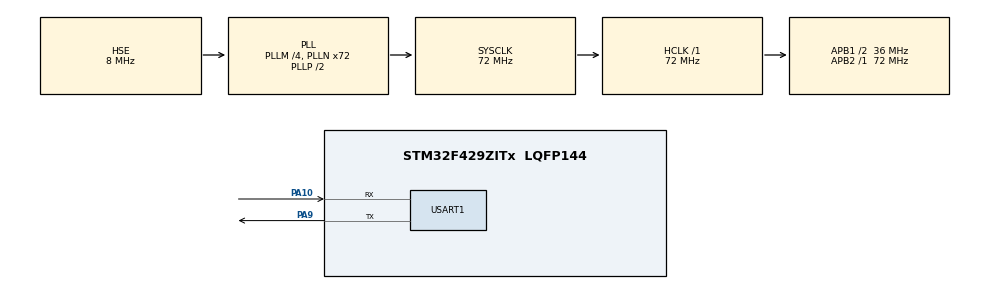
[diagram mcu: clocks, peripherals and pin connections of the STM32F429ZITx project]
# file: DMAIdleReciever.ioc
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Dma.Request0=USART1_RX
Dma.USART1_RX.0.Direction=DMA_PERIPH_TO_MEMORY
Dma.USART1_RX.0.FIFOMode=DMA_FIFOMODE_DISABLE
Dma.USART1_RX.0.Instance=DMA2_Stream2
Dma.USART1_RX.0.MemDataAlignment=DMA_MDATAALIGN_BYTE
Dma.USART1_RX.0.MemInc=DMA_MINC_ENABLE
Dma.USART1_RX.0.Mode=DMA_CIRCULAR
Dma.USART1_RX.0.PeriphDataAlignment=DMA_PDATAALIGN_BYTE
Dma.USART1_RX.0.PeriphInc=DMA_PINC_DISABLE
Dma.USART1_RX.0.Priority=DMA_PRIORITY_LOW
Mcu.Family=STM32F4
Mcu.Name=STM32F429ZITx
Mcu.Package=LQFP144
NVIC.DMA2_Stream2_IRQn=true\:0\:0\:false\:false\:true\:false\:true\:true
NVIC.PriorityGroup=NVIC_PRIORITYGROUP_4
NVIC.USART1_IRQn=true\:0\:0\:false\:false\:true\:true\:true\:true
PA10.Mode=Asynchronous
PA10.Signal=USART1_RX
PA13.Mode=Serial_Wire
PA13.Signal=SYS_JTMS-SWDIO
PA14.Mode=Serial_Wire
PA14.Signal=SYS_JTCK-SWCLK
PA9.Mode=Asynchronous
PA9.Signal=USART1_TX
PH0/OSC_IN.Mode=HSE-External-Oscillator
PH0/OSC_IN.Signal=RCC_OSC_IN
PH1/OSC_OUT.Mode=HSE-External-Oscillator
PH1/OSC_OUT.Signal=RCC_OSC_OUT
ProjectManager.HeapSize=0x200
ProjectManager.StackSize=0x400
ProjectManager.TargetToolchain=STM32CubeIDE
RCC.48MHZClocksFreq_Value=48000000
RCC.AHBFreq_Value=72000000
RCC.APB1CLKDivider=RCC_HCLK_DIV2
RCC.APB1Freq_Value=36000000
RCC.APB1TimFreq_Value=72000000
RCC.APB2Freq_Value=72000000
RCC.APB2TimFreq_Value=72000000
RCC.CortexFreq_Value=72000000
RCC.HCLKFreq_Value=72000000
RCC.HSE_VALUE=8000000
RCC.HSI_VALUE=16000000
RCC.LSE_VALUE=32768
RCC.PLLM=4
RCC.PLLN=72
RCC.PLLQ=3
RCC.PLLSAIN=50
RCC.PLLSourceVirtual=RCC_PLLSOURCE_HSE
RCC.SYSCLKFreq_VALUE=72000000
RCC.SYSCLKSource=RCC_SYSCLKSOURCE_PLLCLK
RCC.VCOOutputFreq_Value=144000000
USART1.VirtualMode=VM_ASYNC
board=STM32F429I-DISC1

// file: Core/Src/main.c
/* USER CODE BEGIN Header */
/**
  ******************************************************************************
  * @file           : main.c
  * @brief          : Main program body
  ******************************************************************************
  * @attention
  *
  * Copyright (c) 2025 STMicroelectronics.
  * All rights reserved.
  *
  * This software is licensed under terms that can be found in the LICENSE file
  * in the root directory of this software component.
  * If no LICENSE file comes with this software, it is provided AS-IS.
  *
  ******************************************************************************
  */
/* USER CODE END Header */
#include "main.h"

/* USER CODE BEGIN Includes */
#include <stdio.h>
#include <string.h>
/* USER CODE END Includes */

DMAIdleReciever_HandleTypeDef hDMAIdleReciever1;
DMA_HandleTypeDef hdma_usart1_rx;

void SystemClock_Config(void);
static void MX_GPIO_Init(void);
static void MX_DMA_Init(void);
static void MX_USART1_DMAIdleReciever_Init(void);

/* USER CODE BEGIN 0 */
#define RXSIZE 256
uint8_t RxData[RXSIZE];
uint8_t FinalBuf[4096];
uint16_t indx1 = 0, indx2=0, rxcplt=0;
int count = 0;
int enable_timer = 0;
uint16_t timer = 0;

void HAL_DMAIdleRecieverEx_RxEventCallback(DMAIdleReciever_HandleTypeDef *hDMAIdleReciever, uint16_t Size)
{
	memcpy (FinalBuf+indx2, RxData+indx1, Size);
	if (Size == RXSIZE)
	{
		rxcplt++;
		indx2 = RXSIZE*rxcplt;
		indx1=0;
	}
	else
	{
		indx2 = indx2 + (Size-indx1);
		indx1 = Size;
	}
	enable_timer = 1;
	timer = 0;

}

/* USER CODE END 0 */

int main(void)
{

  /* MCU Configuration--------------------------------------------------------*/

  /* Reset of all peripherals, Initializes the Flash interface and the Systick. */
  HAL_Init();

  /* Configure the system clock */
  SystemClock_Config();

  /* Initialize all configured peripherals */
  MX_GPIO_Init();
  MX_DMA_Init();
  MX_USART1_DMAIdleReciever_Init();
  /* USER CODE BEGIN 2 */

  HAL_DMAIdleReciever_Transmit(&hDMAIdleReciever1, (uint8_t*)"Hello\r\n", 7, 1000);
  HAL_DMAIdleRecieverEx_ReceiveToIdle_DMA(&hDMAIdleReciever1, RxData, RXSIZE);

  /* USER CODE END 2 */

  /* Infinite loop */
  while (1)
  {

    /* USER CODE BEGIN 3 */
	  if (timer >= 1000){
		  count++;
		  enable_timer = 0;
		  timer=0;
	  }
	/* if (message_ready) {
	  			message_ready = 0;

	  			// Null-terminate for safe string handling
	  			FinalBuf[indx] = '\0';

	  			// Example: Print received GPS/NMEA data back over DMAIdleReciever
	  			char msg[100];
	  			snprintf(msg, sizeof(msg), "Received: %s\r\n", FinalBuf);
	  			HAL_DMAIdleReciever_Transmit(&hDMAIdleReciever1, (uint8_t*) msg, strlen(msg),
	  					HAL_MAX_DELAY);

	  			// Reset buffer
	  			indx = 0;
	  			memset(FinalBuf, 0, sizeof(FinalBuf));
	  		}

	  HAL_Delay(1000);*/

  }
  /* USER CODE END 3 */
}

void SystemClock_Config(void)
{
  RCC_OscInitTypeDef RCC_OscInitStruct = {0};
  RCC_ClkInitTypeDef RCC_ClkInitStruct = {0};

  /** Configure the main internal regulator output voltage
  */
  __HAL_RCC_PWR_CLK_ENABLE();
  __HAL_PWR_VOLTAGESCALING_CONFIG(PWR_REGULATOR_VOLTAGE_SCALE3);

  /** Initializes the RCC Oscillators according to the specified parameters
  * in the RCC_OscInitTypeDef structure.
  */
  RCC_OscInitStruct.OscillatorType = RCC_OSCILLATORTYPE_HSE;
  RCC_OscInitStruct.HSEState = RCC_HSE_ON;
  RCC_OscInitStruct.PLL.PLLState = RCC_PLL_ON;
  RCC_OscInitStruct.PLL.PLLSource = RCC_PLLSOURCE_HSE;
  RCC_OscInitStruct.PLL.PLLM = 4;
  RCC_OscInitStruct.PLL.PLLN = 72;
  RCC_OscInitStruct.PLL.PLLP = RCC_PLLP_DIV2;
  RCC_OscInitStruct.PLL.PLLQ = 3;
  if (HAL_RCC_OscConfig(&RCC_OscInitStruct) != HAL_OK)
  {
    Error_Handler();
  }

  /** Initializes the CPU, AHB and APB buses clocks
  */
  RCC_ClkInitStruct.ClockType = RCC_CLOCKTYPE_HCLK|RCC_CLOCKTYPE_SYSCLK
                              |RCC_CLOCKTYPE_PCLK1|RCC_CLOCKTYPE_PCLK2;
  RCC_ClkInitStruct.SYSCLKSource = RCC_SYSCLKSOURCE_PLLCLK;
  RCC_ClkInitStruct.AHBCLKDivider = RCC_SYSCLK_DIV1;
  RCC_ClkInitStruct.APB1CLKDivider = RCC_HCLK_DIV2;
  RCC_ClkInitStruct.APB2CLKDivider = RCC_HCLK_DIV1;

  if (HAL_RCC_ClockConfig(&RCC_ClkInitStruct, FLASH_LATENCY_2) != HAL_OK)
  {
    Error_Handler();
  }
}

static void MX_USART1_DMAIdleReciever_Init(void)
{

  hDMAIdleReciever1.Instance = USART1;
  hDMAIdleReciever1.Init.BaudRate = 115200;
  hDMAIdleReciever1.Init.WordLength = DMAIdleReciever_WORDLENGTH_8B;
  hDMAIdleReciever1.Init.StopBits = DMAIdleReciever_STOPBITS_1;
  hDMAIdleReciever1.Init.Parity = DMAIdleReciever_PARITY_NONE;
  hDMAIdleReciever1.Init.Mode = DMAIdleReciever_MODE_TX_RX;
  hDMAIdleReciever1.Init.HwFlowCtl = DMAIdleReciever_HWCONTROL_NONE;
  hDMAIdleReciever1.Init.OverSampling = DMAIdleReciever_OVERSAMPLING_16;
  if (HAL_DMAIdleReciever_Init(&hDMAIdleReciever1) != HAL_OK)
  {
    Error_Handler();
  }

}

static void MX_DMA_Init(void)
{

  /* DMA controller clock enable */
  __HAL_RCC_DMA2_CLK_ENABLE();

  /* DMA interrupt init */
  /* DMA2_Stream2_IRQn interrupt configuration */
  HAL_NVIC_SetPriority(DMA2_Stream2_IRQn, 0, 0);
  HAL_NVIC_EnableIRQ(DMA2_Stream2_IRQn);

}

static void MX_GPIO_Init(void)
{

  /* GPIO Ports Clock Enable */
  __HAL_RCC_GPIOH_CLK_ENABLE();
  __HAL_RCC_GPIOA_CLK_ENABLE();

}

void Error_Handler(void)
{
  __disable_irq();
  while (1)
  {
  }
}
